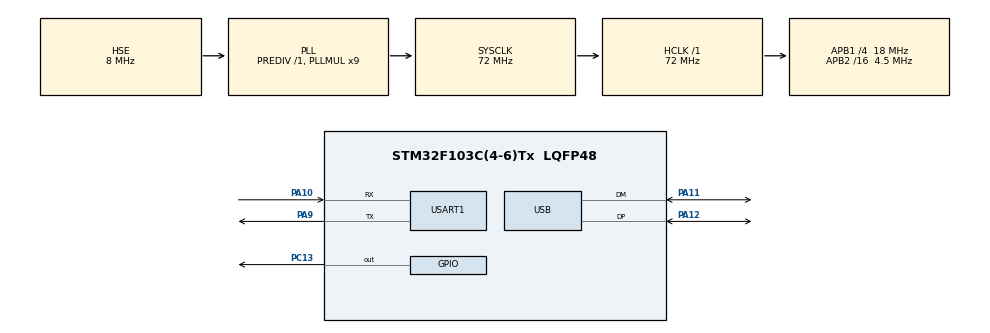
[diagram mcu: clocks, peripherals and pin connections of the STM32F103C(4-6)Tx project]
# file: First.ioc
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Mcu.Family=STM32F1
Mcu.Name=STM32F103C(4-6)Tx
Mcu.Package=LQFP48
NVIC.PriorityGroup=NVIC_PRIORITYGROUP_4
NVIC.USART1_IRQn=true\:0\:0\:false\:false\:true\:true\:true\:true
NVIC.USB_LP_CAN1_RX0_IRQn=true\:0\:0\:false\:false\:true\:false\:true\:true
PA10.Mode=Asynchronous
PA10.Signal=USART1_RX
PA11.Mode=Device
PA11.Signal=USB_DM
PA12.Mode=Device
PA12.Signal=USB_DP
PA13.Mode=Serial_Wire
PA13.Signal=SYS_JTMS-SWDIO
PA14.Mode=Serial_Wire
PA14.Signal=SYS_JTCK-SWCLK
PA9.Mode=Asynchronous
PA9.Signal=USART1_TX
PC13-TAMPER-RTC.Signal=GPIO_Output
PD0-OSC_IN.Mode=HSE-External-Oscillator
PD0-OSC_IN.Signal=RCC_OSC_IN
PD1-OSC_OUT.Mode=HSE-External-Oscillator
PD1-OSC_OUT.Signal=RCC_OSC_OUT
ProjectManager.HeapSize=0x200
ProjectManager.StackSize=0x400
ProjectManager.TargetToolchain=EWARM V8.32
RCC.AHBFreq_Value=72000000
RCC.APB1CLKDivider=RCC_HCLK_DIV4
RCC.APB1Freq_Value=18000000
RCC.APB1TimFreq_Value=36000000
RCC.APB2CLKDivider=RCC_HCLK_DIV16
RCC.APB2Freq_Value=4500000
RCC.APB2TimFreq_Value=9000000
RCC.HCLKFreq_Value=72000000
RCC.PLLMUL=RCC_PLL_MUL9
RCC.PLLSourceVirtual=RCC_PLLSOURCE_HSE
RCC.SYSCLKFreq_VALUE=72000000
RCC.SYSCLKSource=RCC_SYSCLKSOURCE_PLLCLK
RCC.USBFreq_Value=48000000
RCC.USBPrescaler=RCC_USBCLKSOURCE_PLL_DIV1_5
USART1.VirtualMode=VM_ASYNC
USB_DEVICE.CLASS_NAME_FS=CDC
USB_DEVICE.VirtualMode=Cdc
USB_DEVICE.VirtualModeFS=Cdc_FS
VP_USB_DEVICE_VS_USB_DEVICE_CDC_FS.Mode=CDC_FS
board=custom

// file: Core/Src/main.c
/* USER CODE BEGIN Header */
/**
  ******************************************************************************
  * @file           : main.c
  * @brief          : Main program body
  ******************************************************************************
  * @attention
  *
  * Copyright (c) 2025 STMicroelectronics.
  * All rights reserved.
  *
  * This software is licensed under terms that can be found in the LICENSE file
  * in the root directory of this software component.
  * If no LICENSE file comes with this software, it is provided AS-IS.
  *
  ******************************************************************************
  */
/* USER CODE END Header */
#include "main.h"
#include "usart.h"
#include "usb_device.h"
#include "gpio.h"

/* USER CODE BEGIN Includes */

#include <string.h>

#include <stdio.h>
#include "usbd_cdc_if.h"

volatile uint8_t rxReadyFlag = 0;
volatile uint8_t uartTxDone = 1;
uint8_t rxData; // pc에서 수신한 1바이트 데이터를 저장할 변수
char txMsg[50]; // 전송할 문자열을 담을 버퍼

/* USER CODE END Includes */

void SystemClock_Config(void);

int main(void)
{

  /* USER CODE BEGIN 1 */
  uint32_t prevTick = HAL_GetTick();
  /* USER CODE END 1 */

  /* MCU Configuration--------------------------------------------------------*/

  /* Reset of all peripherals, Initializes the Flash interface and the Systick. */
  HAL_Init();

  /* Configure the system clock */
  SystemClock_Config();

  /* Initialize all configured peripherals */
  MX_GPIO_Init();
  MX_USB_DEVICE_Init();
  MX_USART1_UART_Init();
  /* USER CODE BEGIN 2 */

  // 첫 수신 대기  설정 (인터럽트 기반)
  // UART 수신을 인터럽트 방식으로 시작
  // huart1: UART1 설정 정보
  // &rxData: 수신한 데이터를 저장할 주소
  // 1: 1바이트씩 수신하겠다는 의미
  // 1바이트 데이터가 들어오면 STM32가 자동으로 인터럽트를 발생시킨다.
  HAL_UART_Receive_IT(&huart1, &rxData, 1);

  //HAL_Delay(1000);

  /* USER CODE END 2 */

  /* Infinite loop */
  while (1)
  {

    /* USER CODE BEGIN 3 */

    //cdc to pc
    /* char msg[] = "so hard \r\n";
    CDC_Transmit_FS((uint8_t*)msg, strlen(msg));
    HAL_Delay(1000);
    */

    /*
    if(HAL_GetTick() - prevTick >= 250) {
      HAL_GPIO_TogglePin(GPIOC, GPIO_PIN_13);
      prevTick = HAL_GetTick();
    }*/

    if (rxReadyFlag && uartTxDone){
      rxReadyFlag = 0;
      uartTxDone = 0;
      snprintf(txMsg, sizeof(txMsg), "%c\r\n", rxData);
      HAL_UART_Transmit_IT(&huart1, (uint8_t*)txMsg, strlen(txMsg));
      //HAL_UART_Receive_IT(&huart1, &rxData, 1);
    }
  }
  /* USER CODE END 3 */
}

void SystemClock_Config(void)
{
  RCC_OscInitTypeDef RCC_OscInitStruct = {0};
  RCC_ClkInitTypeDef RCC_ClkInitStruct = {0};
  RCC_PeriphCLKInitTypeDef PeriphClkInit = {0};

  /** Initializes the RCC Oscillators according to the specified parameters
  * in the RCC_OscInitTypeDef structure.
  */
  RCC_OscInitStruct.OscillatorType = RCC_OSCILLATORTYPE_HSE;
  RCC_OscInitStruct.HSEState = RCC_HSE_ON;
  RCC_OscInitStruct.HSEPredivValue = RCC_HSE_PREDIV_DIV1;
  RCC_OscInitStruct.HSIState = RCC_HSI_ON;
  RCC_OscInitStruct.PLL.PLLState = RCC_PLL_ON;
  RCC_OscInitStruct.PLL.PLLSource = RCC_PLLSOURCE_HSE;
  RCC_OscInitStruct.PLL.PLLMUL = RCC_PLL_MUL9;
  if (HAL_RCC_OscConfig(&RCC_OscInitStruct) != HAL_OK)
  {
    Error_Handler();
  }

  /** Initializes the CPU, AHB and APB buses clocks
  */
  RCC_ClkInitStruct.ClockType = RCC_CLOCKTYPE_HCLK|RCC_CLOCKTYPE_SYSCLK
                              |RCC_CLOCKTYPE_PCLK1|RCC_CLOCKTYPE_PCLK2;
  RCC_ClkInitStruct.SYSCLKSource = RCC_SYSCLKSOURCE_PLLCLK;
  RCC_ClkInitStruct.AHBCLKDivider = RCC_SYSCLK_DIV1;
  RCC_ClkInitStruct.APB1CLKDivider = RCC_HCLK_DIV4;
  RCC_ClkInitStruct.APB2CLKDivider = RCC_HCLK_DIV16;

  if (HAL_RCC_ClockConfig(&RCC_ClkInitStruct, FLASH_LATENCY_2) != HAL_OK)
  {
    Error_Handler();
  }
  PeriphClkInit.PeriphClockSelection = RCC_PERIPHCLK_USB;
  PeriphClkInit.UsbClockSelection = RCC_USBCLKSOURCE_PLL_DIV1_5;
  if (HAL_RCCEx_PeriphCLKConfig(&PeriphClkInit) != HAL_OK)
  {
    Error_Handler();
  }
}

void Error_Handler(void)
{
  __disable_irq();
  while (1)
  {
  }
}
